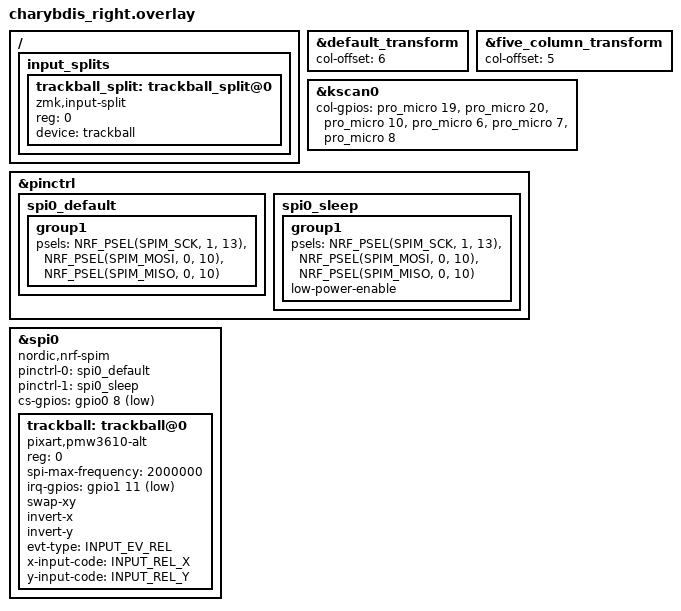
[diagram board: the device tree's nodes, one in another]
/*
 * Copyright (c) 2020 ZMK Contributors
 *
 * SPDX-License-Identifier: MIT
 */

#include "charybdis.dtsi"
#include <zephyr/dt-bindings/input/input-event-codes.h>

&default_transform {
	col-offset = <6>;
};

&five_column_transform {
	col-offset = <5>;
};

&kscan0 {
	col-gpios
		= <&pro_micro 19 (GPIO_ACTIVE_HIGH | GPIO_PULL_DOWN)>
		, <&pro_micro 20 (GPIO_ACTIVE_HIGH | GPIO_PULL_DOWN)>
		, <&pro_micro 10 (GPIO_ACTIVE_HIGH | GPIO_PULL_DOWN)>
		, <&pro_micro 6 (GPIO_ACTIVE_HIGH | GPIO_PULL_DOWN)>
		, <&pro_micro 7 (GPIO_ACTIVE_HIGH | GPIO_PULL_DOWN)>
		, <&pro_micro 8 (GPIO_ACTIVE_HIGH | GPIO_PULL_DOWN)>
		;
};

&pinctrl {
    spi0_default: spi0_default {
        group1 {
            psels = <NRF_PSEL(SPIM_SCK, 1, 13)>,
                <NRF_PSEL(SPIM_MOSI, 0, 10)>,
                <NRF_PSEL(SPIM_MISO, 0, 10)>;
        };
    };

    spi0_sleep: spi0_sleep {
        group1 {
            psels = <NRF_PSEL(SPIM_SCK, 1, 13)>,
                <NRF_PSEL(SPIM_MOSI, 0, 10)>,
                <NRF_PSEL(SPIM_MISO, 0, 10)>;
            low-power-enable;
        };
    };
};

&spi0 {
    status = "okay";
    compatible = "nordic,nrf-spim";
    pinctrl-0 = <&spi0_default>;
    pinctrl-1 = <&spi0_sleep>;
    pinctrl-names = "default", "sleep";
    cs-gpios = <&gpio0 8 GPIO_ACTIVE_LOW>;

    trackball: trackball@0 {
        status = "okay";
        compatible = "pixart,pmw3610-alt";
        reg = <0>;
        spi-max-frequency = <2000000>;
        irq-gpios = <&gpio1 11 (GPIO_ACTIVE_LOW | GPIO_PULL_UP)>;
        /* Axis config via DTS instead of Kconfig */
        swap-xy;
        invert-x;
        invert-y;
        evt-type = <INPUT_EV_REL>;
        x-input-code = <INPUT_REL_X>;
        y-input-code = <INPUT_REL_Y>;
    };
};

/ {
    /* Forward trackball input to central over split link */
    input_splits {
        #address-cells = <1>;
        #size-cells = <0>;

        trackball_split: trackball_split@0 {
            compatible = "zmk,input-split";
            reg = <0>;
            device = <&trackball>;
        };
    };
};
